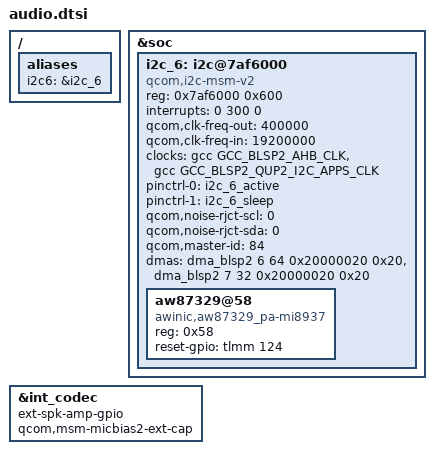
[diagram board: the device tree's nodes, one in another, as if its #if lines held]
/* From stock msm8917.dtsi */
/ {
	aliases {
		i2c6 = &i2c_6;
	};
};
&soc {
	/* WARNING: Copy */
	i2c_6: i2c@7af6000 { /* BLSP2 QUP1 */
		compatible = "qcom,i2c-msm-v2";
		#address-cells = <1>;
		#size-cells = <0>;
		reg-names = "qup_phys_addr";
		reg = <0x7af6000 0x600>;
		interrupt-names = "qup_irq";
		interrupts = <0 300 0>;
		qcom,clk-freq-out = <400000>;
		qcom,clk-freq-in  = <19200000>;
		clock-names = "iface_clk", "core_clk";
		clocks = <&gcc GCC_BLSP2_AHB_CLK>,
			<&gcc GCC_BLSP2_QUP2_I2C_APPS_CLK>;

		pinctrl-names = "i2c_active", "i2c_sleep";
		pinctrl-0 = <&i2c_6_active>;
		pinctrl-1 = <&i2c_6_sleep>;
		qcom,noise-rjct-scl = <0>;
		qcom,noise-rjct-sda = <0>;
		qcom,master-id = <84>;
		dmas = <&dma_blsp2 6 64 0x20000020 0x20>,
			<&dma_blsp2 7 32 0x20000020 0x20>;
		dma-names = "tx", "rx";
		status = "disabled";
	};
};

/* From stock msm-audio.dtsi */
&int_codec {
#ifndef MI8937_V2
	ext-spk-amp-gpio = <&tlmm 124 0>; // WARNING: Overridden by below
#endif
};

/* From stock msm8917-qrd_S88508.dtsi */
&i2c_6 {
	status = "ok";
	aw87329@58 {
#ifdef CONFIG_SND_SOC_AW87329_MI8937
		compatible = "awinic,aw87329_pa-mi8937";
#else
		compatible = "awinic,aw87329_pa";
#endif
		reg = <0x58>;
		reset-gpio = <&tlmm 124 0>;
		status = "ok";
	};
};
&int_codec {
#ifndef MI8937_V2
	ext-spk-amp-gpio;
#endif
	qcom,msm-micbias2-ext-cap;
};
